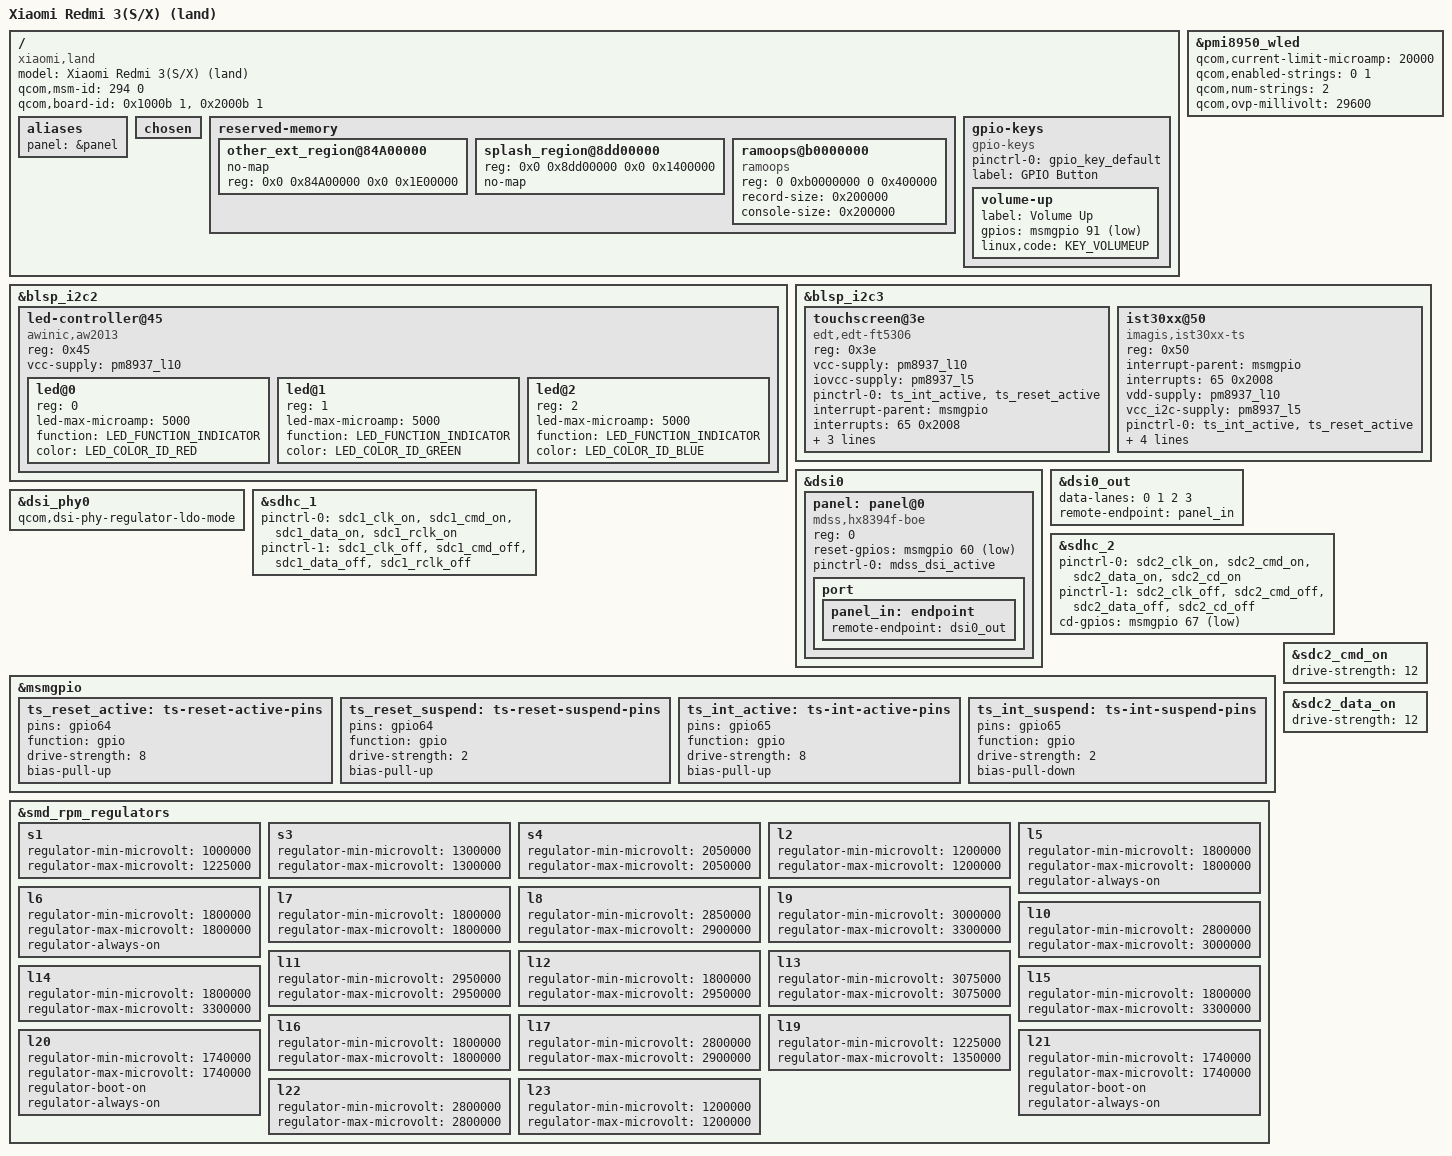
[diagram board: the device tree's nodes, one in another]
/dts-v1/;

#include "msm8940-pm8937.dtsi"
#include "pmi8950.dtsi"
#include <dt-bindings/leds/common.h>
#include <dt-bindings/gpio/gpio.h>

/ {
	model = "Xiaomi Redmi 3(S/X) (land)";
	compatible = "xiaomi,land", "qcom,msm8937";

	qcom,msm-id = <294 0>;
	qcom,board-id= <0x1000b 1>, <0x2000b 1>;

	aliases {
		panel = &panel;
	};

	chosen {};

	reserved-memory {
		/delete-node/other_ext_region@85b00000;
		/delete-node/splash_region@90000000;
		
		other_ext_region@84A00000 {
			no-map;
			reg = <0x0 0x84A00000 0x0 0x1E00000>;
		};
		
		splash_region@8dd00000 {
			reg = <0x0 0x8dd00000 0x0 0x1400000>;
			no-map;
		};

		ramoops@b0000000 {
			compatible = "ramoops";
			reg = <0 0xb0000000 0 0x400000>;
			record-size = <0x200000>;
			console-size = <0x200000>;
		};
	};

	gpio-keys {
		compatible = "gpio-keys";

		pinctrl-names = "default";
		pinctrl-0 = <&gpio_key_default>;

		label = "GPIO Button";

		volume-up {
			label = "Volume Up";
			gpios = <&msmgpio 91 GPIO_ACTIVE_LOW>;
			linux,code = <KEY_VOLUMEUP>;
		};
	};
};

&pmi8950_wled {
	status = "okay";

	/* Don't copy-paste! See pmi8950.dtsi */

	qcom,current-limit-microamp = <20000>;
	qcom,enabled-strings = <0 1>;
	qcom,num-strings = <2>;
	qcom,ovp-millivolt = <29600>;
};

&blsp_i2c2 {
	status = "okay";
	led-controller@45 {
		#address-cells = <1>;
		#size-cells = <0>;

		compatible = "awinic,aw2013";

		reg = <0x45>;

		vcc-supply = <&pm8937_l10>;

		led@0 {
			reg = <0>;
			led-max-microamp = <5000>;
			function = LED_FUNCTION_INDICATOR;
			color = <LED_COLOR_ID_RED>;
		};
		led@1 {
			reg = <1>;
			led-max-microamp = <5000>;
			function = LED_FUNCTION_INDICATOR;
			color = <LED_COLOR_ID_GREEN>;
		};
		led@2 {
			reg = <2>;
			led-max-microamp = <5000>;
			function = LED_FUNCTION_INDICATOR;
			color = <LED_COLOR_ID_BLUE>;
		};
	};
};

&blsp_i2c3 {
	status = "okay";

	touchscreen@3e {
		compatible = "edt,edt-ft5306", "edt,edt-ft5x06";
		reg = <0x3e>;
		vcc-supply = <&pm8937_l10>;
		iovcc-supply = <&pm8937_l5>;
		pinctrl-names = "default";
		pinctrl-0 = <&ts_int_active &ts_reset_active>;
		interrupt-parent = <&msmgpio>;
		interrupts = <65 0x2008>;
		reset-gpios = <&msmgpio 64 GPIO_ACTIVE_LOW>;
		touchscreen-size-x = <720>;
		touchscreen-size-y = <1280>;
	};
	
	ist30xx@50 {
		compatible = "imagis,ist30xx-ts"; // Need to port driver
		reg = <0x50>;
		interrupt-parent = <&msmgpio>;
		interrupts = <65 0x2008>;
		vdd-supply = <&pm8937_l10>;
		vcc_i2c-supply = <&pm8937_l5>;
		pinctrl-names = "pmx_ts_active"; // ,"pmx_ts_suspend", "pmx_ts_release";
		pinctrl-0 = <&ts_int_active &ts_reset_active>;
		//pinctrl-1 = <&ts_int_suspend &ts_reset_suspend>;
		//pinctrl-2 = <&ts_release>;
		ist30xx,name = "ist30xx";
		ist30xx,family-id = <0x36>;
		ist30xx,reset-gpio = <&msmgpio 64 0x00>;
		ist30xx,irq-gpio = <&msmgpio 65 0x2008>;
	};
};

&dsi0 {
	panel: panel@0 {
		compatible = "mdss,hx8394f-boe";
		reg = <0>;
		
		reset-gpios = <&msmgpio 60 GPIO_ACTIVE_LOW>;
		
		pinctrl-names = "default";
		pinctrl-0 = <&mdss_dsi_active>;

		port {
			panel_in: endpoint {
				remote-endpoint = <&dsi0_out>;
			};
		};
	};
};

&dsi0_out {
	data-lanes = <0 1 2 3>;
	remote-endpoint = <&panel_in>;
};

&dsi_phy0 {
	qcom,dsi-phy-regulator-ldo-mode;
};

&sdhc_1 {
	status = "okay";

	pinctrl-names = "default", "sleep";
	pinctrl-0 = <&sdc1_clk_on &sdc1_cmd_on &sdc1_data_on &sdc1_rclk_on>;
	pinctrl-1 = <&sdc1_clk_off &sdc1_cmd_off &sdc1_data_off &sdc1_rclk_off>;
};

&sdhc_2 {
	status = "okay";

	pinctrl-names = "default", "sleep";
	pinctrl-0 = <&sdc2_clk_on &sdc2_cmd_on &sdc2_data_on &sdc2_cd_on>;
	pinctrl-1 = <&sdc2_clk_off &sdc2_cmd_off &sdc2_data_off &sdc2_cd_off>;

	cd-gpios = <&msmgpio 67 GPIO_ACTIVE_LOW>;
};

&msmgpio {
	ts_reset_active: ts-reset-active-pins {
		pins = "gpio64";
		function = "gpio";
		drive-strength = <8>;
		bias-pull-up;
	};

	ts_reset_suspend: ts-reset-suspend-pins {
		pins = "gpio64";
		function = "gpio";
		drive-strength = <2>;
		bias-pull-up;
	};

	ts_int_active: ts-int-active-pins {
		pins = "gpio65";
		function = "gpio";
		drive-strength = <8>;
		bias-pull-up;
	};

	ts_int_suspend: ts-int-suspend-pins {
		pins = "gpio65";
		function = "gpio";
		drive-strength = <2>;
		bias-pull-down;
	};
};

&sdc2_cmd_on {
	drive-strength = <12>;
};

&sdc2_data_on {
	drive-strength = <12>;
};

&smd_rpm_regulators {
	s1 {
		regulator-min-microvolt = <1000000>;
		regulator-max-microvolt = <1225000>;
	};
	s3 {
		regulator-min-microvolt = <1300000>;
		regulator-max-microvolt = <1300000>;
	};
	s4 {
		regulator-min-microvolt = <2050000>;
		regulator-max-microvolt = <2050000>;
	};
	l2 {
		regulator-min-microvolt = <1200000>;
		regulator-max-microvolt = <1200000>;
	};
	l5 {
		regulator-min-microvolt = <1800000>;
		regulator-max-microvolt = <1800000>;
		regulator-always-on;
	};
	l6 {
		regulator-min-microvolt = <1800000>;
		regulator-max-microvolt = <1800000>;
		regulator-always-on;
	};
	l7 {
		regulator-min-microvolt = <1800000>;
		regulator-max-microvolt = <1800000>;
	};
	l8 {
		regulator-min-microvolt = <2850000>;
		regulator-max-microvolt = <2900000>;
	};
	l9 {
		regulator-min-microvolt = <3000000>;
		regulator-max-microvolt = <3300000>;
	};
	l10 {
		regulator-min-microvolt = <2800000>;
		regulator-max-microvolt = <3000000>;
	};
	l11 {
		regulator-min-microvolt = <2950000>;
		regulator-max-microvolt = <2950000>;
	};
	l12 {
		regulator-min-microvolt = <1800000>;
		regulator-max-microvolt = <2950000>;
	};
	l13 {
		regulator-min-microvolt = <3075000>;
		regulator-max-microvolt = <3075000>;
	};
	l14 {
		regulator-min-microvolt = <1800000>;
		regulator-max-microvolt = <3300000>;
	};
	l15 {
		regulator-min-microvolt = <1800000>;
		regulator-max-microvolt = <3300000>;
	};
	l16 {
		regulator-min-microvolt = <1800000>;
		regulator-max-microvolt = <1800000>;
	};
	l17 {
		regulator-min-microvolt = <2800000>;
		regulator-max-microvolt = <2900000>;
	};
	l19 {
		regulator-min-microvolt = <1225000>;
		regulator-max-microvolt = <1350000>;
	};
	l20 {
		regulator-min-microvolt = <1740000>;
		regulator-max-microvolt = <1740000>;
		regulator-boot-on;
		regulator-always-on;
	};
	l21 {
		regulator-min-microvolt = <1740000>;
		regulator-max-microvolt = <1740000>;
		regulator-boot-on;
		regulator-always-on;
	};
	l22 {
		regulator-min-microvolt = <2800000>;
		regulator-max-microvolt = <2800000>;
	};
	l23 {
		regulator-min-microvolt = <1200000>;
		regulator-max-microvolt = <1200000>;
	};
};
